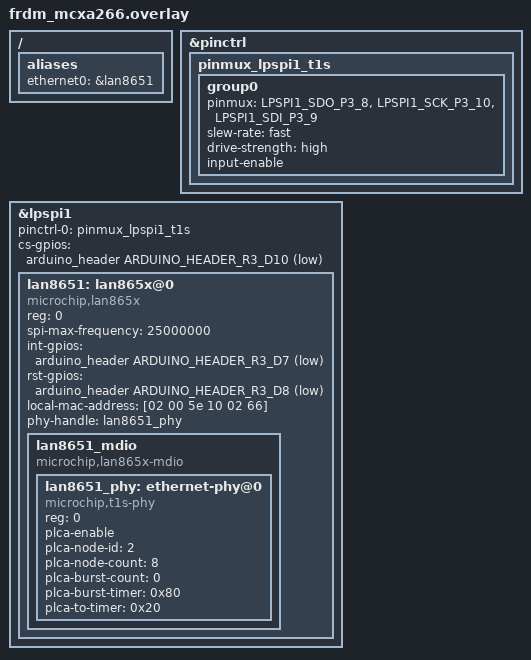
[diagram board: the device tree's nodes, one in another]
#include <zephyr/dt-bindings/gpio/arduino-header-r3.h>

/ {
	aliases {
		ethernet0 = &lan8651;
	};
};

&pinctrl {
	pinmux_lpspi1_t1s: pinmux_lpspi1_t1s {
		group0 {
			pinmux = <LPSPI1_SDO_P3_8>,
				 <LPSPI1_SCK_P3_10>,
				 <LPSPI1_SDI_P3_9>;
			slew-rate = "fast";
			drive-strength = "high";
			input-enable;
		};
	};
};

&lpspi1 {
	status = "okay";
	pinctrl-0 = <&pinmux_lpspi1_t1s>;
	pinctrl-names = "default";
	cs-gpios = <&arduino_header ARDUINO_HEADER_R3_D10 GPIO_ACTIVE_LOW>;

	lan8651: lan865x@0 {
		compatible = "microchip,lan865x";
		reg = <0>;
		spi-max-frequency = <25000000>;
		int-gpios = <&arduino_header ARDUINO_HEADER_R3_D7 GPIO_ACTIVE_LOW>;
		rst-gpios = <&arduino_header ARDUINO_HEADER_R3_D8 GPIO_ACTIVE_LOW>;
		local-mac-address = [02 00 5e 10 02 66];
		phy-handle = <&lan8651_phy>;

		lan8651_mdio: lan8651_mdio {
			compatible = "microchip,lan865x-mdio";
			#address-cells = <1>;
			#size-cells = <0>;
			status = "okay";

			lan8651_phy: ethernet-phy@0 {
				compatible = "microchip,t1s-phy";
				reg = <0>;
				plca-enable;
				plca-node-id = <2>;
				plca-node-count = <8>;
				plca-burst-count = <0>;
				plca-burst-timer = <0x80>;
				plca-to-timer = <0x20>;
				status = "okay";
			};
		};

		status = "okay";
	};
};
